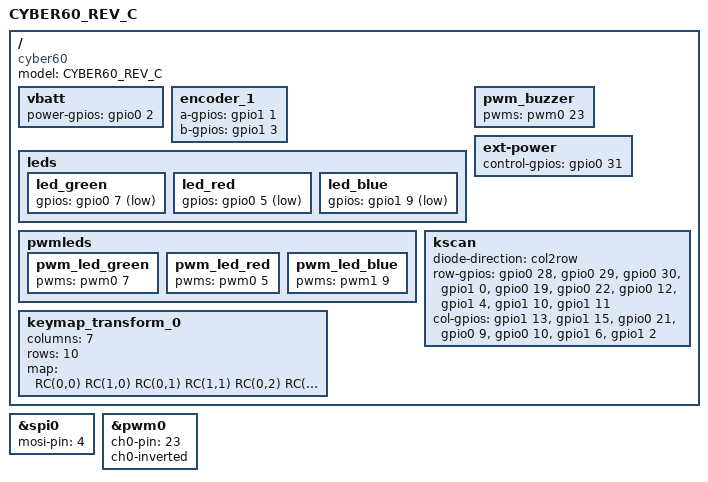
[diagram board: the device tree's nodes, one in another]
/*
 * Copyright (c) 2020-2021 Stefan Sundin (4pplet)
 * Copyright (c) 2021 Megamind (megamind4089)
 *
 * SPDX-License-Identifier: MIT
 */

/ {
    model = "CYBER60_REV_C";
    compatible = "cyber60", "Rev C";

    vbatt {
        power-gpios = <&gpio0 2 GPIO_ACTIVE_HIGH>; // P0.02
    };

    encoder_1 {
        a-gpios = <&gpio1 1 (GPIO_ACTIVE_HIGH | GPIO_PULL_UP)>;
        b-gpios = <&gpio1 3 (GPIO_ACTIVE_HIGH | GPIO_PULL_UP)>;
    };

    leds {
        led_green {
            gpios = <&gpio0 7 GPIO_ACTIVE_LOW>;
        };
        led_red {
            gpios = <&gpio0 5 GPIO_ACTIVE_LOW>;
        };
        led_blue {
            gpios = <&gpio1 9 GPIO_ACTIVE_LOW>;
        };
    };
    pwmleds {
        pwm_led_green {
            pwms = <&pwm0 7>;
        };
        pwm_led_red {
            pwms = <&pwm0 5>;
        };
        pwm_led_blue {
            pwms = <&pwm1 9>;
        };
    };

    // Buzzer on pin P0.23
    pwm_buzzer {
        pwms = <&pwm0 23>;
    };

    ext-power {
        control-gpios = <&gpio0 31 GPIO_ACTIVE_HIGH>;
    };

    keymap_transform_0 {
        columns = <7>;
        rows = <10>;
        map = <
            RC(0,0) RC(1,0) RC(0,1) RC(1,1) RC(0,2) RC(1,2) RC(0,3) RC(1,3) RC(0,4) RC(1,4) RC(0,5) RC(1,5) RC(0,6) RC(1,6) RC(3,6)
            RC(2,0) RC(3,0) RC(2,1) RC(3,1) RC(2,2) RC(3,2) RC(2,3) RC(3,3) RC(2,4) RC(3,4) RC(2,5) RC(3,5) RC(2,6) RC(5,6)
            RC(4,0) RC(5,0) RC(4,1) RC(5,1) RC(4,2) RC(5,2) RC(4,3) RC(5,3) RC(4,4) RC(5,4) RC(4,5) RC(5,5)  RC(4,6) RC(7,6)
            RC(6,0) RC(7,0) RC(6,1) RC(7,1) RC(6,2) RC(7,2) RC(6,3) RC(7,3) RC(6,4) RC(7,4)    RC(6,5)     RC(7,5) RC(8,6) RC(6,6)
            RC(8,0) RC(9,0) RC(8,1) RC(9,1) RC(8,3) RC(9,3) RC(8,4) RC(9,4) RC(8,5)  RC(9,5)
            RC(9,6) // rotary sw
            >;
    };
    kscan {
        diode-direction = "col2row";
        row-gpios
            = <&gpio0 28  (GPIO_ACTIVE_HIGH | GPIO_PULL_DOWN)>
            , <&gpio0 29 (GPIO_ACTIVE_HIGH | GPIO_PULL_DOWN)>
            , <&gpio0 30 (GPIO_ACTIVE_HIGH | GPIO_PULL_DOWN)>
            , <&gpio1 0 (GPIO_ACTIVE_HIGH | GPIO_PULL_DOWN)>
            , <&gpio0 19 (GPIO_ACTIVE_HIGH | GPIO_PULL_DOWN)>
            , <&gpio0 22 (GPIO_ACTIVE_HIGH | GPIO_PULL_DOWN)>
            , <&gpio0 12 (GPIO_ACTIVE_HIGH | GPIO_PULL_DOWN)>
            , <&gpio1 4 (GPIO_ACTIVE_HIGH | GPIO_PULL_DOWN)>
            , <&gpio1 10 (GPIO_ACTIVE_HIGH | GPIO_PULL_DOWN)>
            , <&gpio1 11 (GPIO_ACTIVE_HIGH | GPIO_PULL_DOWN)>
            ;
        col-gpios
            = <&gpio1 13  GPIO_ACTIVE_HIGH>
            , <&gpio1 15  GPIO_ACTIVE_HIGH>
            , <&gpio0 21  GPIO_ACTIVE_HIGH>
            , <&gpio0 9 GPIO_ACTIVE_HIGH>
            , <&gpio0 10 GPIO_ACTIVE_HIGH>
            , <&gpio1 6  GPIO_ACTIVE_HIGH>
            , <&gpio1 2 GPIO_ACTIVE_HIGH>
            ;
    };
};

&spi0 {
    // Underglow data: P0.04
    mosi-pin = <4>;
};

&pwm0 {
    ch0-pin = <23>;
    ch0-inverted;
};
